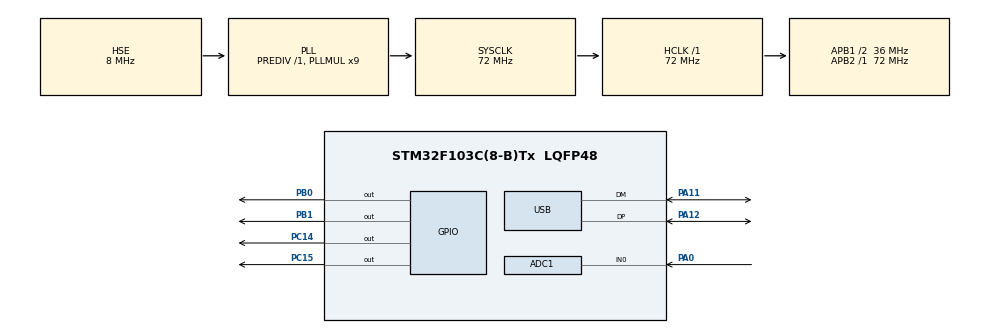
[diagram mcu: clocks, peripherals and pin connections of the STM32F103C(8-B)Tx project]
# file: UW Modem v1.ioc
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ADC1.Channel-0\#ChannelRegularConversion=ADC_CHANNEL_0
ADC1.ContinuousConvMode=ENABLE
ADC1.NbrOfConversionFlag=1
ADC1.Rank-0\#ChannelRegularConversion=1
ADC1.SamplingTime-0\#ChannelRegularConversion=ADC_SAMPLETIME_1CYCLE_5
ADC1.master=1
Mcu.Family=STM32F1
Mcu.Name=STM32F103C(8-B)Tx
Mcu.Package=LQFP48
NVIC.PriorityGroup=NVIC_PRIORITYGROUP_4
NVIC.USB_LP_CAN1_RX0_IRQn=true\:0\:0\:false\:false\:true\:false
PA0-WKUP.Signal=ADCx_IN0
PA11.Mode=Device
PA11.Signal=USB_DM
PA12.Mode=Device
PA12.Signal=USB_DP
PA13.Mode=Serial_Wire
PA13.Signal=SYS_JTMS-SWDIO
PA14.Mode=Serial_Wire
PA14.Signal=SYS_JTCK-SWCLK
PB0.Signal=GPIO_Output
PB1.Signal=GPIO_Output
PC14-OSC32_IN.Signal=GPIO_Output
PC15-OSC32_OUT.Signal=GPIO_Output
PD0-OSC_IN.Mode=HSE-External-Oscillator
PD0-OSC_IN.Signal=RCC_OSC_IN
PD1-OSC_OUT.Mode=HSE-External-Oscillator
PD1-OSC_OUT.Signal=RCC_OSC_OUT
ProjectManager.HeapSize=0x200
ProjectManager.StackSize=0x400
ProjectManager.TargetToolchain=SW4STM32
RCC.ADCPresc=RCC_ADCPCLK2_DIV6
RCC.AHBFreq_Value=72000000
RCC.APB1CLKDivider=RCC_HCLK_DIV2
RCC.APB1Freq_Value=36000000
RCC.APB1TimFreq_Value=72000000
RCC.APB2Freq_Value=72000000
RCC.APB2TimFreq_Value=72000000
RCC.HCLKFreq_Value=72000000
RCC.PLLMUL=RCC_PLL_MUL9
RCC.SYSCLKFreq_VALUE=72000000
RCC.SYSCLKSource=RCC_SYSCLKSOURCE_PLLCLK
RCC.USBFreq_Value=48000000
RCC.USBPrescaler=RCC_USBCLKSOURCE_PLL_DIV1_5
SH.ADCx_IN0.0=ADC1_IN0,IN0
USB_DEVICE.CLASS_NAME_FS=CDC
USB_DEVICE.PRODUCT_STRING_CDC_FS=UW_Modem
USB_DEVICE.VirtualMode=Cdc
USB_DEVICE.VirtualModeFS=Cdc_FS
VP_USB_DEVICE_VS_USB_DEVICE_CDC_FS.Mode=CDC_FS
board=custom

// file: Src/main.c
/**
  ******************************************************************************
  * @file           : main.c
  * @brief          : Main program body
  ******************************************************************************
  * This notice applies to any and all portions of this file
  * that are not between comment pairs USER CODE BEGIN and
  * USER CODE END. Other portions of this file, whether
  * inserted by the user or by software development tools
  * are owned by their respective copyright owners.
  *
  * Copyright (c) 2018 STMicroelectronics International N.V.
  * All rights reserved.
  *
  * Redistribution and use in source and binary forms, with or without
  * modification, are permitted, provided that the following conditions are met:
  *
  * 1. Redistribution of source code must retain the above copyright notice,
  *    this list of conditions and the following disclaimer.
  * 2. Redistributions in binary form must reproduce the above copyright notice,
  *    this list of conditions and the following disclaimer in the documentation
  *    and/or other materials provided with the distribution.
  * 3. Neither the name of STMicroelectronics nor the names of other
  *    contributors to this software may be used to endorse or promote products
  *    derived from this software without specific written permission.
  * 4. This software, including modifications and/or derivative works of this
  *    software, must execute solely and exclusively on microcontroller or
  *    microprocessor devices manufactured by or for STMicroelectronics.
  * 5. Redistribution and use of this software other than as permitted under
  *    this license is void and will automatically terminate your rights under
  *    this license.
  *
  * THIS SOFTWARE IS PROVIDED BY STMICROELECTRONICS AND CONTRIBUTORS "AS IS"
  * AND ANY EXPRESS, IMPLIED OR STATUTORY WARRANTIES, INCLUDING, BUT NOT
  * LIMITED TO, THE IMPLIED WARRANTIES OF MERCHANTABILITY, FITNESS FOR A
  * PARTICULAR PURPOSE AND NON-INFRINGEMENT OF THIRD PARTY INTELLECTUAL PROPERTY
  * RIGHTS ARE DISCLAIMED TO THE FULLEST EXTENT PERMITTED BY LAW. IN NO EVENT
  * SHALL STMICROELECTRONICS OR CONTRIBUTORS BE LIABLE FOR ANY DIRECT, INDIRECT,
  * INCIDENTAL, SPECIAL, EXEMPLARY, OR CONSEQUENTIAL DAMAGES (INCLUDING, BUT NOT
  * LIMITED TO, PROCUREMENT OF SUBSTITUTE GOODS OR SERVICES; LOSS OF USE, DATA,
  * OR PROFITS; OR BUSINESS INTERRUPTION) HOWEVER CAUSED AND ON ANY THEORY OF
  * LIABILITY, WHETHER IN CONTRACT, STRICT LIABILITY, OR TORT (INCLUDING
  * NEGLIGENCE OR OTHERWISE) ARISING IN ANY WAY OUT OF THE USE OF THIS SOFTWARE,
  * EVEN IF ADVISED OF THE POSSIBILITY OF SUCH DAMAGE.
  *
  ******************************************************************************
  */
#include "main.h"
#include "stm32f1xx_hal.h"
#include "usb_device.h"

ADC_HandleTypeDef hadc1;

/* USER CODE BEGIN PV */
/* Private variables ---------------------------------------------------------*/

/* USER CODE END PV */

void SystemClock_Config(void);
static void MX_GPIO_Init(void);
static void MX_ADC1_Init(void);

/* USER CODE BEGIN PFP */
/* Private function prototypes -----------------------------------------------*/
void delayUS_DWT(uint32_t us);
uint16_t read_adc(void);
void send_data(uint8_t data);
void pulse_one(void);
void pulse_zero(void);
/* USER CODE END PFP */

int main(void)
{

  /* MCU Configuration----------------------------------------------------------*/

  /* Reset of all peripherals, Initializes the Flash interface and the Systick. */
  HAL_Init();

  /* Configure the system clock */
  SystemClock_Config();

  /* Initialize all configured peripherals */
  MX_GPIO_Init();
  MX_ADC1_Init();
  MX_USB_DEVICE_Init();
  /* USER CODE BEGIN 2 */
  HAL_ADC_Start(&hadc1);
  CoreDebug->DEMCR |= CoreDebug_DEMCR_TRCENA_Msk;
  DWT->CTRL |= DWT_CTRL_CYCCNTENA_Msk;
  /* USER CODE END 2 */

  /* Infinite loop */
  while (1)
  {
	/*
	uint16_t ADCsample = 500 ;
	uint16_t ADCValue[ADCsample];
	ADCValue[0] = read_adc();

	if (ADCValue[0]>512){

		HAL_GPIO_WritePin(GPIOC, GPIO_PIN_13, 0);

		for (int i=1; i<ADCsample;i++){

			ADCValue[i] = read_adc();
		}

		int w = 0;
		int count = 0;
		int prev,p,c = 0;
		uint8_t data=0;
		int bit_cnt = 7;

		for (int j=0;j<ADCsample;j++){

			if (ADCValue[j]>512)
			{
				count+=1;
			}
			else
			{
				w=count+prev;
				c=count;
				p=prev;
				count=0;
				prev=0;
			}

			//if (w>0)
			//{
				//uint8_t buff[20];
				//sprintf(buff,"%d\r\n",w);
				//CDC_Transmit_FS(buff, strlen(buff));
				//HAL_Delay(1);
			//}

			if((w>=1)&&(w<4))
			{
				//Serial.println(" one");
				data |= (1<<bit_cnt);
				bit_cnt--;
				if (bit_cnt==-1) bit_cnt=7;
				w=0;
			}
			else if((w>=4)&&(w<8))
			{
				//Serial.println(" zero");
				data &= ~(1<<bit_cnt);
				bit_cnt--;
				if (bit_cnt==-1) bit_cnt=7;
				w=0;
			}
			else  w=0;
		}
		uint8_t buff[20];
		sprintf(buff,"Data: %d\r\n",data);
		CDC_Transmit_FS(buff, strlen(buff));
		//HAL_Delay(1);
		//CDC_Transmit_FS("-----\r\n", 7);
		HAL_GPIO_WritePin(GPIOC, GPIO_PIN_13, 1);

		//HAL_Delay(1000);
	}
	*/
	HAL_GPIO_WritePin(GPIOC, GPIO_PIN_13, 0);
	send_data(65);
	HAL_GPIO_WritePin(GPIOC, GPIO_PIN_13, 1);
	//HAL_Delay(1);
  }

}

void delayUS_DWT(uint32_t us) {
	//DWT->CTRL |= 1 ; // enable the counter
	DWT->CYCCNT = 0; // reset the counter
	volatile uint32_t cycles = (SystemCoreClock/1000000L)*us;
	volatile uint32_t start = DWT->CYCCNT;
	do  {
	} while(DWT->CYCCNT - start < cycles);
	//DWT->CTRL |= 0 ; // enable the counter
}

uint16_t read_adc(void){

	if (HAL_ADC_PollForConversion(&hadc1, 1000000) == HAL_OK)
	{
		return HAL_ADC_GetValue(&hadc1);
	}
	return 0;

}

void send_data(uint8_t data)
{
     for (int i=0;i<8;i++)
     {
         if (((data>>(7-i))&1)==0)
         {
              pulse_zero();
         }
         else
         {
              pulse_one();
         }
     }
}

void pulse_one(void)
{
	HAL_GPIO_WritePin(GPIOB, GPIO_PIN_0, 0);
	//HAL_GPIO_WritePin(GPIOB, GPIO_PIN_1, 1);
	delayUS_DWT(12);
	HAL_GPIO_WritePin(GPIOB, GPIO_PIN_0, 1);
	//HAL_GPIO_WritePin(GPIOB, GPIO_PIN_1, 0);
    delayUS_DWT(12);
    //HAL_GPIO_WritePin(GPIOB, GPIO_PIN_0, 0);
    //HAL_GPIO_WritePin(GPIOB, GPIO_PIN_1, 0);
}

void pulse_zero(void)
{
	HAL_GPIO_WritePin(GPIOB, GPIO_PIN_0, 0);
	//HAL_GPIO_WritePin(GPIOB, GPIO_PIN_1, 1);
	delayUS_DWT(12);
	HAL_GPIO_WritePin(GPIOB, GPIO_PIN_0, 1);
	//HAL_GPIO_WritePin(GPIOB, GPIO_PIN_1, 0);
	delayUS_DWT(12);
	//HAL_GPIO_WritePin(GPIOB, GPIO_PIN_0, 0);
	//HAL_GPIO_WritePin(GPIOB, GPIO_PIN_1, 0);
}

void SystemClock_Config(void)
{

  RCC_OscInitTypeDef RCC_OscInitStruct;
  RCC_ClkInitTypeDef RCC_ClkInitStruct;
  RCC_PeriphCLKInitTypeDef PeriphClkInit;

    /**Initializes the CPU, AHB and APB busses clocks
    */
  RCC_OscInitStruct.OscillatorType = RCC_OSCILLATORTYPE_HSE;
  RCC_OscInitStruct.HSEState = RCC_HSE_ON;
  RCC_OscInitStruct.HSEPredivValue = RCC_HSE_PREDIV_DIV1;
  RCC_OscInitStruct.HSIState = RCC_HSI_ON;
  RCC_OscInitStruct.PLL.PLLState = RCC_PLL_ON;
  RCC_OscInitStruct.PLL.PLLSource = RCC_PLLSOURCE_HSE;
  RCC_OscInitStruct.PLL.PLLMUL = RCC_PLL_MUL9;
  if (HAL_RCC_OscConfig(&RCC_OscInitStruct) != HAL_OK)
  {
    _Error_Handler(__FILE__, __LINE__);
  }

    /**Initializes the CPU, AHB and APB busses clocks
    */
  RCC_ClkInitStruct.ClockType = RCC_CLOCKTYPE_HCLK|RCC_CLOCKTYPE_SYSCLK
                              |RCC_CLOCKTYPE_PCLK1|RCC_CLOCKTYPE_PCLK2;
  RCC_ClkInitStruct.SYSCLKSource = RCC_SYSCLKSOURCE_PLLCLK;
  RCC_ClkInitStruct.AHBCLKDivider = RCC_SYSCLK_DIV1;
  RCC_ClkInitStruct.APB1CLKDivider = RCC_HCLK_DIV2;
  RCC_ClkInitStruct.APB2CLKDivider = RCC_HCLK_DIV1;

  if (HAL_RCC_ClockConfig(&RCC_ClkInitStruct, FLASH_LATENCY_2) != HAL_OK)
  {
    _Error_Handler(__FILE__, __LINE__);
  }

  PeriphClkInit.PeriphClockSelection = RCC_PERIPHCLK_ADC|RCC_PERIPHCLK_USB;
  PeriphClkInit.AdcClockSelection = RCC_ADCPCLK2_DIV6;
  PeriphClkInit.UsbClockSelection = RCC_USBCLKSOURCE_PLL_DIV1_5;
  if (HAL_RCCEx_PeriphCLKConfig(&PeriphClkInit) != HAL_OK)
  {
    _Error_Handler(__FILE__, __LINE__);
  }

    /**Configure the Systick interrupt time
    */
  HAL_SYSTICK_Config(HAL_RCC_GetHCLKFreq()/1000);

    /**Configure the Systick
    */
  HAL_SYSTICK_CLKSourceConfig(SYSTICK_CLKSOURCE_HCLK);

  /* SysTick_IRQn interrupt configuration */
  HAL_NVIC_SetPriority(SysTick_IRQn, 0, 0);
}

/* ADC1 init function */
static void MX_ADC1_Init(void)
{

  ADC_ChannelConfTypeDef sConfig;

    /**Common config
    */
  hadc1.Instance = ADC1;
  hadc1.Init.ScanConvMode = ADC_SCAN_DISABLE;
  hadc1.Init.ContinuousConvMode = ENABLE;
  hadc1.Init.DiscontinuousConvMode = DISABLE;
  hadc1.Init.ExternalTrigConv = ADC_SOFTWARE_START;
  hadc1.Init.DataAlign = ADC_DATAALIGN_RIGHT;
  hadc1.Init.NbrOfConversion = 1;
  if (HAL_ADC_Init(&hadc1) != HAL_OK)
  {
    _Error_Handler(__FILE__, __LINE__);
  }

    /**Configure Regular Channel
    */
  sConfig.Channel = ADC_CHANNEL_0;
  sConfig.Rank = ADC_REGULAR_RANK_1;
  sConfig.SamplingTime = ADC_SAMPLETIME_1CYCLE_5;
  if (HAL_ADC_ConfigChannel(&hadc1, &sConfig) != HAL_OK)
  {
    _Error_Handler(__FILE__, __LINE__);
  }

}

/** Configure pins as
        * Analog
        * Input
        * Output
        * EVENT_OUT
        * EXTI
*/
static void MX_GPIO_Init(void)
{

  GPIO_InitTypeDef GPIO_InitStruct;

  /* GPIO Ports Clock Enable */
  __HAL_RCC_GPIOC_CLK_ENABLE();
  __HAL_RCC_GPIOD_CLK_ENABLE();
  __HAL_RCC_GPIOA_CLK_ENABLE();
  __HAL_RCC_GPIOB_CLK_ENABLE();

  /*Configure GPIO pin Output Level */
  HAL_GPIO_WritePin(GPIOC, GPIO_PIN_13|GPIO_PIN_14|GPIO_PIN_15, GPIO_PIN_RESET);

  /*Configure GPIO pin Output Level */
  HAL_GPIO_WritePin(GPIOB, GPIO_PIN_0|GPIO_PIN_1, GPIO_PIN_RESET);

  /*Configure GPIO pins : PC13 PC14 PC15 */
  GPIO_InitStruct.Pin = GPIO_PIN_13|GPIO_PIN_14|GPIO_PIN_15;
  GPIO_InitStruct.Mode = GPIO_MODE_OUTPUT_PP;
  GPIO_InitStruct.Pull = GPIO_NOPULL;
  GPIO_InitStruct.Speed = GPIO_SPEED_FREQ_LOW;
  HAL_GPIO_Init(GPIOC, &GPIO_InitStruct);

  /*Configure GPIO pins : PB0 PB1 */
  GPIO_InitStruct.Pin = GPIO_PIN_0|GPIO_PIN_1;
  GPIO_InitStruct.Mode = GPIO_MODE_OUTPUT_PP;
  GPIO_InitStruct.Pull = GPIO_NOPULL;
  GPIO_InitStruct.Speed = GPIO_SPEED_FREQ_LOW;
  HAL_GPIO_Init(GPIOB, &GPIO_InitStruct);

}

void _Error_Handler(char *file, int line)
{
  while(1)
  {
  }
}

/************************ (C) COPYRIGHT STMicroelectronics *****END OF FILE****/
